# ADC12_1 register map
Vendor: Texas Instruments
Peripheral module from a debugger description file (folder msp430).
Registers are 16-bit, access not given, no defined reset value unless marked. A register's access mark holds for its fields unless they carry their own. Offsets are as the file gives them; lines under a group give offsets from that group; [hi:lo] are bit positions; {n}, {i} and the like mark numbered series; 'fields as' and 'values as' point back to an identical list; <NAME> marks a mode.

## ADC12
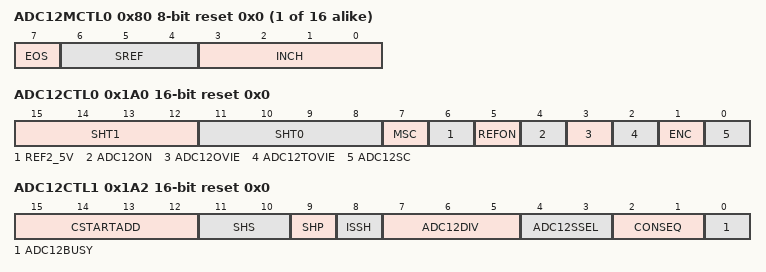
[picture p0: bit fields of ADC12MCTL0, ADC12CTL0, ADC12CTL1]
{0x80+i} ADC12MCTL{i} 8-bit rw reset 0x0 (i=0..15) — ADC12 Memory Control {i}
  [7] EOS — ADC12 End of Sequence
  [6:4] SREF — ADC12 Select Reference Bit 0
    {v}=ADC12 Select Reference {v} (v=0..7)
  [3:0] INCH — ADC12 Input Channel Select Bit 0
    {v}=ADC12 Input Channel {v} (v=0..15)
{0x140+2i} ADC12MEM{i} (i=0..15) — ADC12 Conversion Memory {i}
0x1A0 ADC12CTL0 rw reset 0x0 — ADC12 Control 0
  [15:12] SHT1 — ADC12 Sample Hold 0 Select 0
    {v}=ADC12 Sample Hold 1 Select Bit: {v} (v=0..15)
  [11:8] SHT0 — ADC12 Sample Hold 0 Select 0
    {v}=ADC12 Sample Hold 0 Select Bit: {v} (v=0..15)
  [7] MSC — ADC12 Multiple SampleConversion
  [6] REF2_5V — ADC12 Ref 0:1.5V / 1:2.5V
  [5] REFON — ADC12 Reference on
  [4] ADC12ON — ADC12 On/enable
  [3] ADC12OVIE — ADC12 Overflow interrupt enable
  [2] ADC12TOVIE — ADC12 Timer Overflow interrupt enable
  [1] ENC — ADC12 Enable Conversion
  [0] ADC12SC — ADC12 Start Conversion
0x1A2 ADC12CTL1 rw reset 0x0 — ADC12 Control 1
  [15:12] CSTARTADD — ADC12 Conversion Start Address 0
    {v}=ADC12 Conversion Start Address: {v} (v=0..15)
  [11:10] SHS — ADC12 Sample/Hold Source 0
    {v}=ADC12 Sample/Hold Source: {v} (v=0..3)
  [9] SHP — ADC12 Sample/Hold Pulse Mode
  [8] ISSH — ADC12 Invert Sample Hold Signal
  [7:5] ADC12DIV — ADC12 Clock Divider Select 0
    {v}=ADC12 Clock Divider Select: {v} (v=0..7)
  [4:3] ADC12SSEL — ADC12 Clock Source Select 0
    {v}=ADC12 Clock Source Select: {v} (v=0..3)
  [2:1] CONSEQ — ADC12 Conversion Sequence Select 0
    {v}=ADC12 Conversion Sequence Select: {v} (v=0..3)
  [0] ADC12BUSY
0x1A4 ADC12IFG — ADC12 Interrupt Flag
0x1A6 ADC12IE — ADC12 Interrupt Enable
0x1A8 ADC12IV — ADC12 Interrupt Vector Word
